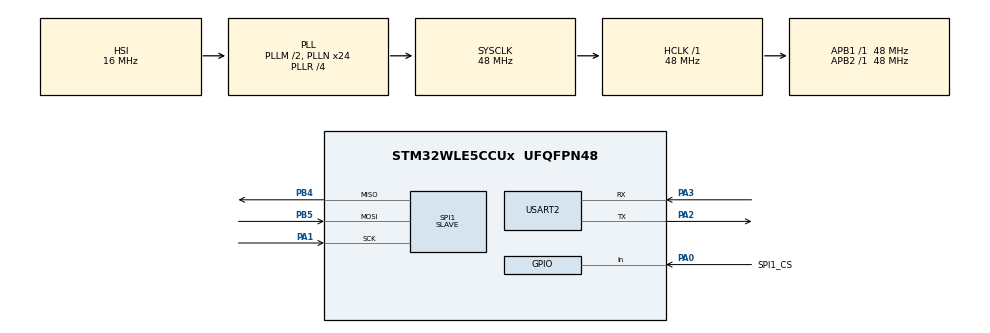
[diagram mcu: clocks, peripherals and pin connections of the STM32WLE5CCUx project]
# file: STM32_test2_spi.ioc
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Mcu.Family=STM32WL
Mcu.Name=STM32WLE5CCUx
Mcu.Package=UFQFPN48
NVIC.PriorityGroup=NVIC_PRIORITYGROUP_4
OSC_IN.Mode=HSE-External-Oscillator
OSC_IN.Signal=RCC_OSC_IN
OSC_OUT.Mode=HSE-External-Oscillator
OSC_OUT.Signal=RCC_OSC_OUT
PA0.GPIO_Label=SPI1_CS
PA0.Signal=GPIO_Input
PA1.Mode=Full_Duplex_Slave
PA1.Signal=SPI1_SCK
PA13.Mode=Trace_Asynchronous_SW
PA13.Signal=DEBUG_JTMS-SWDIO
PA14.Mode=Trace_Asynchronous_SW
PA14.Signal=DEBUG_JTCK-SWCLK
PA2.Mode=Asynchronous
PA2.Signal=USART2_TX
PA3.Mode=Asynchronous
PA3.Signal=USART2_RX
PB3.Mode=Trace_Asynchronous_SW
PB3.Signal=DEBUG_JTDO-SWO
PB4.Mode=Full_Duplex_Slave
PB4.Signal=SPI1_MISO
PB5.Mode=Full_Duplex_Slave
PB5.Signal=SPI1_MOSI
ProjectManager.HeapSize=0x200
ProjectManager.StackSize=0x400
ProjectManager.TargetToolchain=STM32CubeIDE
RCC.AHBFreq_Value=48000000
RCC.APB1Freq_Value=48000000
RCC.APB1TimFreq_Value=48000000
RCC.APB2Freq_Value=48000000
RCC.APB2TimFreq_Value=48000000
RCC.APB3Freq_Value=48000000
RCC.CortexFreq_Value=48000000
RCC.HCLKFreq_Value=48000000
RCC.HSEPRES=2
RCC.HSE_VALUE=32000000
RCC.HSI_VALUE=16000000
RCC.LSE_VALUE=32768
RCC.PLLM=RCC_PLLM_DIV2
RCC.PLLN=24
RCC.PLLR=RCC_PLLR_DIV4
RCC.PLLSourceVirtual=RCC_PLLSOURCE_HSI
RCC.SYSCLKFreq_VALUE=48000000
RCC.SYSCLKSource=RCC_SYSCLKSOURCE_PLLCLK
RCC.VCOOutputFreq_Value=192000000
SPI1.DataSize=SPI_DATASIZE_8BIT
SPI1.Direction=SPI_DIRECTION_2LINES
SPI1.Mode=SPI_MODE_SLAVE
SPI1.VirtualType=VM_SLAVE
USART2.VirtualMode-Asynchronous=VM_ASYNC
board=custom

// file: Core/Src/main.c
/* USER CODE BEGIN Header */
/**
  ******************************************************************************
  * @file           : main.c
  * @brief          : Main program body
  ******************************************************************************
  * @attention
  *
  * Copyright (c) 2026 STMicroelectronics.
  * All rights reserved.
  *
  * This software is licensed under terms that can be found in the LICENSE file
  * in the root directory of this software component.
  * If no LICENSE file comes with this software, it is provided AS-IS.
  *
  ******************************************************************************
  */
/* USER CODE END Header */
#include "main.h"
#include "spi.h"
#include "usart.h"
#include "gpio.h"

void SystemClock_Config(void);

int main(void)
{

  /* MCU Configuration--------------------------------------------------------*/

  /* Reset of all peripherals, Initializes the Flash interface and the Systick. */
  HAL_Init();

  /* Configure the system clock */
  SystemClock_Config();

  /* Initialize all configured peripherals */
  MX_GPIO_Init();
  MX_SPI1_Init();
  MX_USART2_UART_Init();

  /* Infinite loop */
  while (1)
  {

    /* USER CODE BEGIN 3 */
    uint8_t txData[] = "Hello ESP32!";
    uint8_t rxData[13] = {0}; // Same size as txData

    // Wait for master (ESP32) to initiate the SPI transfer.
    // The STM32 will block here until the master clocks out the expected number of bytes.
    HAL_SPI_TransmitReceive(&hspi1, txData, rxData, sizeof(txData)-1, HAL_MAX_DELAY);

    // Optional delay to give ESP32 time to print or process
    //HAL_Delay(100);
  }
  /* USER CODE END 3 */
}

void SystemClock_Config(void)
{
  RCC_OscInitTypeDef RCC_OscInitStruct = {0};
  RCC_ClkInitTypeDef RCC_ClkInitStruct = {0};

  /** Configure the main internal regulator output voltage
  */
  __HAL_PWR_VOLTAGESCALING_CONFIG(PWR_REGULATOR_VOLTAGE_SCALE1);

  /** Initializes the CPU, AHB and APB buses clocks
  */
  RCC_OscInitStruct.OscillatorType = RCC_OSCILLATORTYPE_HSI;
  RCC_OscInitStruct.HSIState = RCC_HSI_ON;
  RCC_OscInitStruct.HSICalibrationValue = RCC_HSICALIBRATION_DEFAULT;
  RCC_OscInitStruct.PLL.PLLState = RCC_PLL_ON;
  RCC_OscInitStruct.PLL.PLLSource = RCC_PLLSOURCE_HSI;
  RCC_OscInitStruct.PLL.PLLM = RCC_PLLM_DIV2;
  RCC_OscInitStruct.PLL.PLLN = 24;
  RCC_OscInitStruct.PLL.PLLP = RCC_PLLP_DIV2;
  RCC_OscInitStruct.PLL.PLLR = RCC_PLLR_DIV4;
  RCC_OscInitStruct.PLL.PLLQ = RCC_PLLQ_DIV2;
  if (HAL_RCC_OscConfig(&RCC_OscInitStruct) != HAL_OK)
  {
    Error_Handler();
  }

  /** Configure the SYSCLKSource, HCLK, PCLK1 and PCLK2 clocks dividers
  */
  RCC_ClkInitStruct.ClockType = RCC_CLOCKTYPE_HCLK3|RCC_CLOCKTYPE_HCLK
                              |RCC_CLOCKTYPE_SYSCLK|RCC_CLOCKTYPE_PCLK1
                              |RCC_CLOCKTYPE_PCLK2;
  RCC_ClkInitStruct.SYSCLKSource = RCC_SYSCLKSOURCE_PLLCLK;
  RCC_ClkInitStruct.AHBCLKDivider = RCC_SYSCLK_DIV1;
  RCC_ClkInitStruct.APB1CLKDivider = RCC_HCLK_DIV1;
  RCC_ClkInitStruct.APB2CLKDivider = RCC_HCLK_DIV1;
  RCC_ClkInitStruct.AHBCLK3Divider = RCC_SYSCLK_DIV1;

  if (HAL_RCC_ClockConfig(&RCC_ClkInitStruct, FLASH_LATENCY_2) != HAL_OK)
  {
    Error_Handler();
  }
}

void Error_Handler(void)
{
  __disable_irq();
  while (1)
  {
  }
}
